# CEC1712H_N2_SX register map
Vendor: Microchip
Registers are 32-bit, read-write, reset 0x0 unless marked. A register's access mark holds for its fields unless they carry their own. Addresses are absolute, and some are shared; only a register's first bit layout is shown; [hi:lo] are bit positions.

## PWM5
0x40005850 CNT_ON
0x40005854 CNT_OFF reset 0xFFFF
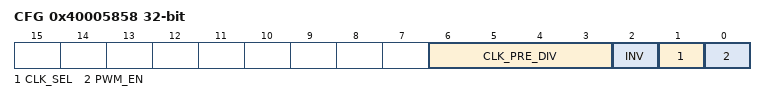
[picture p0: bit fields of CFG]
0x40005858 CFG
  [6:3] CLK_PRE_DIV — The Clock source for the 16-bit down counter (see PWMx Counter ON Time Register and PWMx Counter OFF Time Register) is determined by bit D1 of this register. The Clock source is then divided by the value of Pre-Divider+1 and the resulting signal determines the rate at which the down counter will be decremented. For example, a Pre-Divider value of 1 divides the input clock by 2 and a value of 2 divides the input clock by 3. A Pre-Divider of 0 will disable the Pre-Divider option.
  [2] INV — 1= PWM_OUTPUT ON State is active low; 0=PWM_OUTPUT ON State is active high.
  [1] CLK_SEL — This bit determines the clock source used by the PWM duty cycle and frequency control logic. 1=CLOCK_LOW. 0=CLOCK_HIGH
  [0] PWM_EN — When the PWM_ENABLE is set to 0 the internal counters are reset and the internal state machine is set to the OFF state. In addition, the PWM_OUTPUT signal is set to the inactive state as determined by the Invert bit. The PWMx Counter ON Time Register and PWMx Counter OFF Time Register are not affected by the PWM_ENABLE bit and may be read and written while the PWM enable bit is 0. 1=Enabled (default); 0=Disabled (gates clocks to save power).

## PWM6
0x40005860 CNT_ON
0x40005864 CNT_OFF reset 0xFFFF
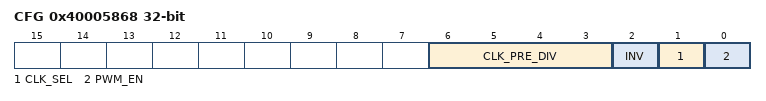
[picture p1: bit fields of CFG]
0x40005868 CFG
  [6:3] CLK_PRE_DIV — The Clock source for the 16-bit down counter (see PWMx Counter ON Time Register and PWMx Counter OFF Time Register) is determined by bit D1 of this register. The Clock source is then divided by the value of Pre-Divider+1 and the resulting signal determines the rate at which the down counter will be decremented. For example, a Pre-Divider value of 1 divides the input clock by 2 and a value of 2 divides the input clock by 3. A Pre-Divider of 0 will disable the Pre-Divider option.
  [2] INV — 1= PWM_OUTPUT ON State is active low; 0=PWM_OUTPUT ON State is active high.
  [1] CLK_SEL — This bit determines the clock source used by the PWM duty cycle and frequency control logic. 1=CLOCK_LOW. 0=CLOCK_HIGH
  [0] PWM_EN — When the PWM_ENABLE is set to 0 the internal counters are reset and the internal state machine is set to the OFF state. In addition, the PWM_OUTPUT signal is set to the inactive state as determined by the Invert bit. The PWMx Counter ON Time Register and PWMx Counter OFF Time Register are not affected by the PWM_ENABLE bit and may be read and written while the PWM enable bit is 0. 1=Enabled (default); 0=Disabled (gates clocks to save power).

## PWM7
0x40005870 CNT_ON
0x40005874 CNT_OFF reset 0xFFFF
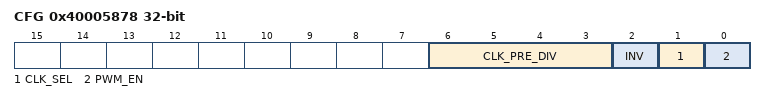
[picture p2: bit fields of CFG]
0x40005878 CFG
  [6:3] CLK_PRE_DIV — The Clock source for the 16-bit down counter (see PWMx Counter ON Time Register and PWMx Counter OFF Time Register) is determined by bit D1 of this register. The Clock source is then divided by the value of Pre-Divider+1 and the resulting signal determines the rate at which the down counter will be decremented. For example, a Pre-Divider value of 1 divides the input clock by 2 and a value of 2 divides the input clock by 3. A Pre-Divider of 0 will disable the Pre-Divider option.
  [2] INV — 1= PWM_OUTPUT ON State is active low; 0=PWM_OUTPUT ON State is active high.
  [1] CLK_SEL — This bit determines the clock source used by the PWM duty cycle and frequency control logic. 1=CLOCK_LOW. 0=CLOCK_HIGH
  [0] PWM_EN — When the PWM_ENABLE is set to 0 the internal counters are reset and the internal state machine is set to the OFF state. In addition, the PWM_OUTPUT signal is set to the inactive state as determined by the Invert bit. The PWMx Counter ON Time Register and PWMx Counter OFF Time Register are not affected by the PWM_ENABLE bit and may be read and written while the PWM enable bit is 0. 1=Enabled (default); 0=Disabled (gates clocks to save power).
